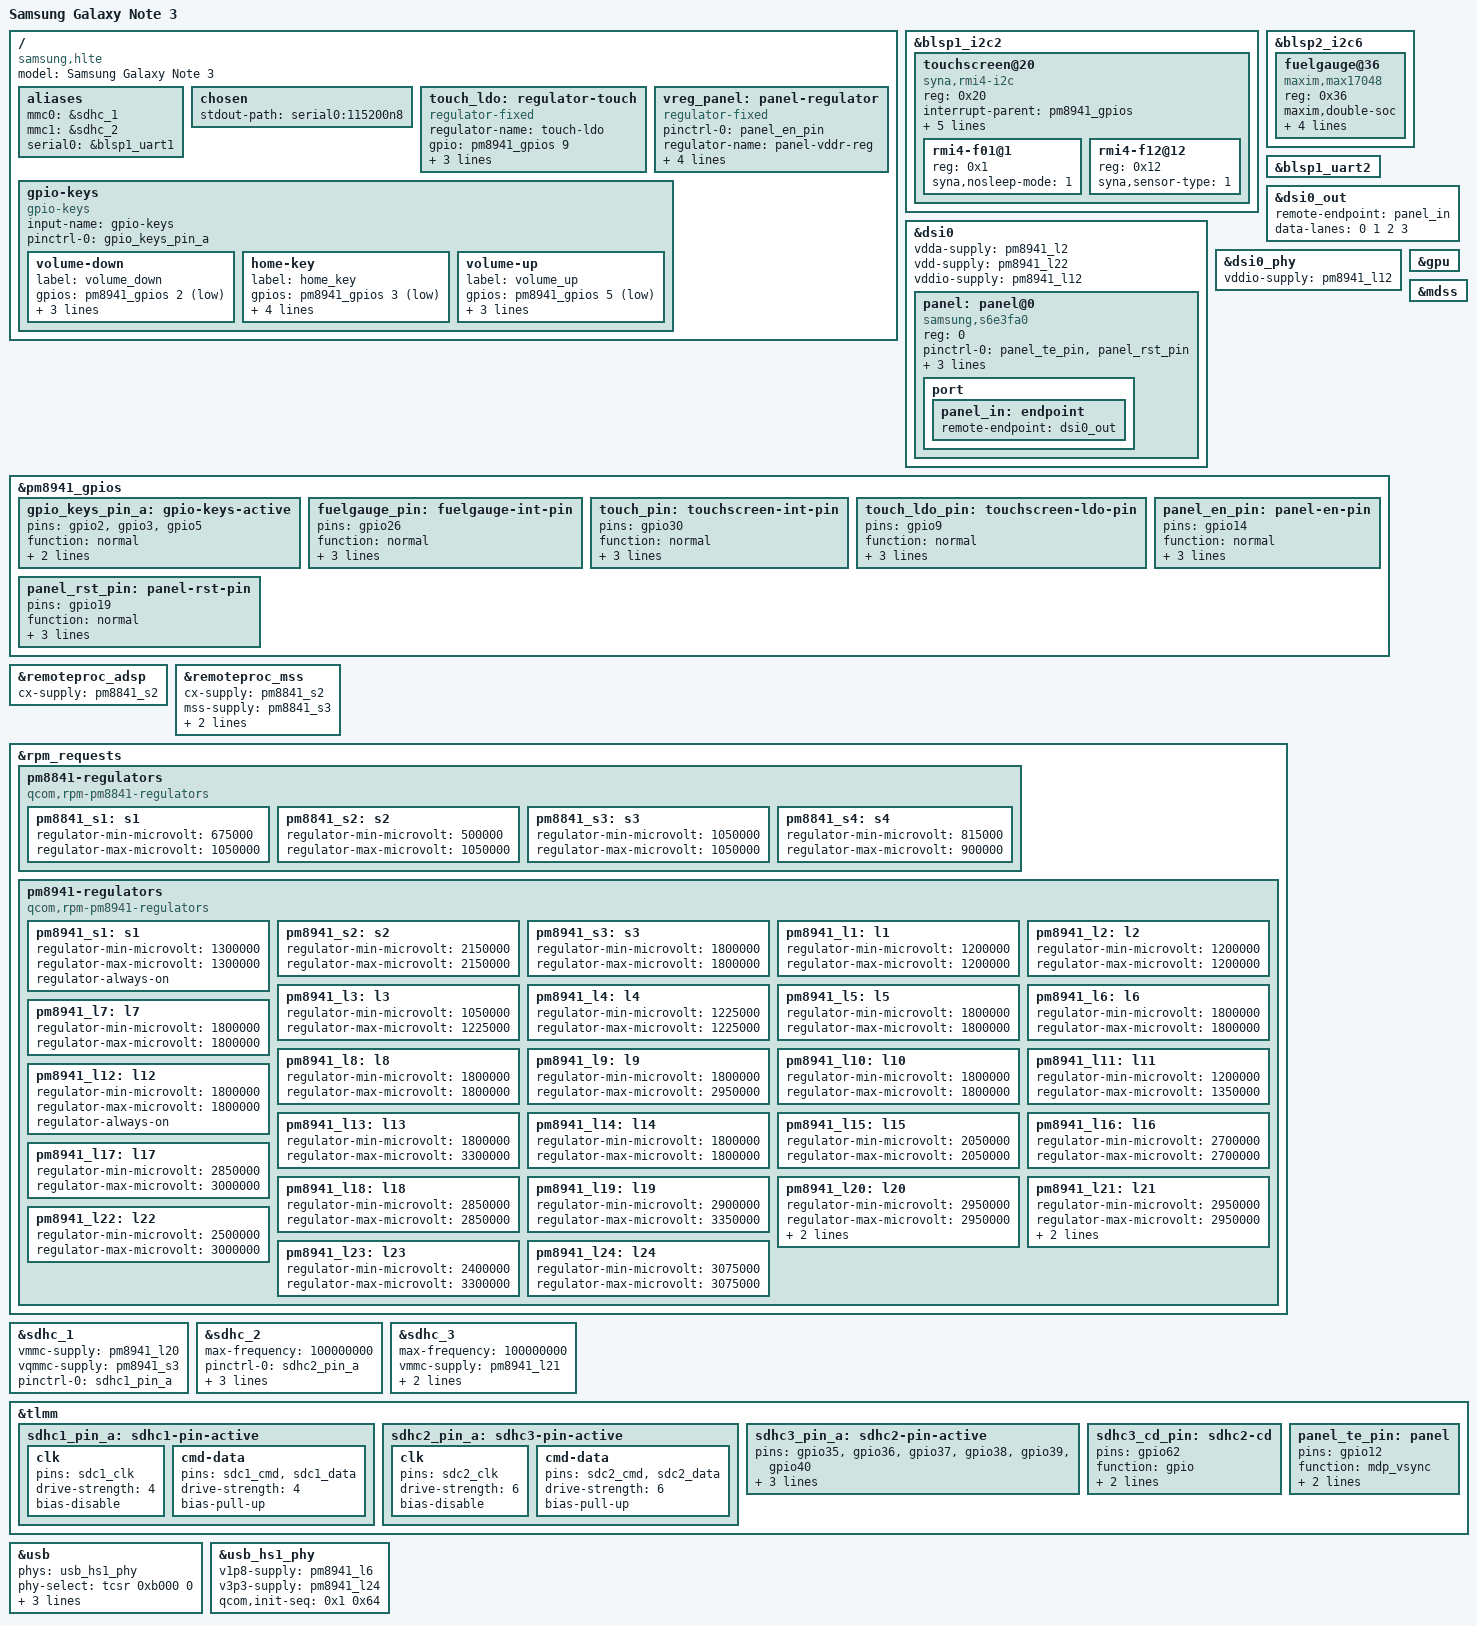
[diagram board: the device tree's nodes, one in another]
// SPDX-License-Identifier: GPL-2.0
#include "qcom-msm8974.dtsi"
#include "qcom-pm8841.dtsi"
#include "qcom-pm8941.dtsi"
#include <dt-bindings/input/input.h>
#include <dt-bindings/leds/common.h>
#include <dt-bindings/pinctrl/qcom,pmic-gpio.h>

/ {
	model = "Samsung Galaxy Note 3";
	compatible = "samsung,hlte", "qcom,msm8974";

	aliases {
		mmc0 = &sdhc_1; /* SDC1 eMMC slot */
		mmc1 = &sdhc_2; /* SDC2 SD card slot */
		serial0 = &blsp1_uart1;
	};

	chosen {
		stdout-path = "serial0:115200n8";
	};

	touch_ldo: regulator-touch {
		compatible = "regulator-fixed";
		regulator-name = "touch-ldo";
		gpio = <&pm8941_gpios 9 GPIO_ACTIVE_HIGH>;
		enable-active-high;
		regulator-boot-on;

		pinctrl-names = "default";
		pinctrl-0 = <&touch_ldo_pin>;
	};

	vreg_panel: panel-regulator {
		compatible = "regulator-fixed";

		pinctrl-names = "default";
		pinctrl-0 = <&panel_en_pin>;

		regulator-name = "panel-vddr-reg";
		regulator-min-microvolt = <1500000>;
		regulator-max-microvolt = <1500000>;

		gpio = <&pm8941_gpios 14 GPIO_ACTIVE_HIGH>;
		enable-active-high;
	};

	gpio-keys {
		compatible = "gpio-keys";
		input-name = "gpio-keys";

		pinctrl-names = "default";
		pinctrl-0 = <&gpio_keys_pin_a>;

		volume-down {
			label = "volume_down";
			gpios = <&pm8941_gpios 2 GPIO_ACTIVE_LOW>;
			linux,input-type = <1>;
			linux,code = <KEY_VOLUMEDOWN>;
			debounce-interval = <15>;
		};

		home-key {
			label = "home_key";
			gpios = <&pm8941_gpios 3 GPIO_ACTIVE_LOW>;
			linux,input-type = <1>;
			linux,code = <KEY_HOMEPAGE>;
			wakeup-source;
			debounce-interval = <15>;
		};

		volume-up {
			label = "volume_up";
			gpios = <&pm8941_gpios 5 GPIO_ACTIVE_LOW>;
			linux,input-type = <1>;
			linux,code = <KEY_VOLUMEUP>;
			debounce-interval = <15>;
		};
	};
};

&blsp1_i2c2 {
	status = "okay";

	touchscreen@20 {
		compatible = "syna,rmi4-i2c";
		reg = <0x20>;

		interrupt-parent = <&pm8941_gpios>;
		interrupts = <30 IRQ_TYPE_EDGE_FALLING>;

		vdd-supply = <&pm8941_l10>;
		vio-supply = <&touch_ldo>;

		pinctrl-names = "default";
		pinctrl-0 = <&touch_pin>;

		syna,startup-delay-ms = <100>;

		#address-cells = <1>;
		#size-cells = <0>;

		rmi4-f01@1 {
			reg = <0x1>;
			syna,nosleep-mode = <1>;
		};

		rmi4-f12@12 {
			reg = <0x12>;
			syna,sensor-type = <1>;
		};
	};
};

&blsp2_i2c6 {
	status = "okay";

	fuelgauge@36 {
		compatible = "maxim,max17048";
		reg = <0x36>;

		maxim,double-soc;
		maxim,rcomp = /bits/ 8 <0x56>;

		interrupt-parent = <&pm8941_gpios>;
		interrupts = <26 IRQ_TYPE_EDGE_FALLING>;

		pinctrl-names = "default";
		pinctrl-0 = <&fuelgauge_pin>;
	};
};

&blsp1_uart2 {
	status = "okay";
};

&dsi0 {
	status = "okay";

	vdda-supply = <&pm8941_l2>;
	vdd-supply = <&pm8941_l22>;
	vddio-supply = <&pm8941_l12>;

	panel: panel@0 {
		reg = <0>;
		compatible = "samsung,s6e3fa0";

		pinctrl-names = "default";
		pinctrl-0 = <&panel_te_pin &panel_rst_pin>;

		iovdd-supply = <&pm8941_l12>;
		vddr-supply = <&vreg_panel>;

		reset-gpios = <&pm8941_gpios 19 GPIO_ACTIVE_LOW>;

		port {
			panel_in: endpoint {
				remote-endpoint = <&dsi0_out>;
			};
		};
	};
};

&dsi0_out {
	remote-endpoint = <&panel_in>;
	data-lanes = <0 1 2 3>;
};

&dsi0_phy {
	status = "okay";

	vddio-supply = <&pm8941_l12>;
};

&gpu {
	status = "okay";
};

&mdss {
	status = "okay";
};

&pm8941_gpios {
	gpio_keys_pin_a: gpio-keys-active {
		pins = "gpio2", "gpio3", "gpio5";
		function = "normal";

		bias-pull-up;
		power-source = <PM8941_GPIO_S3>;
	};

	fuelgauge_pin: fuelgauge-int-pin {
		pins = "gpio26";
		function = "normal";
		bias-disable;
		input-enable;
		power-source = <PM8941_GPIO_S3>;
	};

	touch_pin: touchscreen-int-pin {
		pins = "gpio30";
		function = "normal";
		bias-disable;
		input-enable;
		power-source = <PM8941_GPIO_S3>;
	};

	touch_ldo_pin: touchscreen-ldo-pin {
		pins = "gpio9";
		function = "normal";

		output-high;
		power-source = <PM8941_GPIO_S3>;
		qcom,drive-strength = <PMIC_GPIO_STRENGTH_HIGH>;
	};

	panel_en_pin: panel-en-pin {
		pins = "gpio14";
		function = "normal";
		bias-pull-up;
		power-source = <PM8941_GPIO_S3>;
		qcom,drive-strength = <PMIC_GPIO_STRENGTH_LOW>;
	};

	panel_rst_pin: panel-rst-pin {
		pins = "gpio19";
		function = "normal";
		bias-disable;
		power-source = <PM8941_GPIO_S3>;
		qcom,drive-strength = <PMIC_GPIO_STRENGTH_LOW>;
	};
};

&remoteproc_adsp {
	cx-supply = <&pm8841_s2>;
};

&remoteproc_mss {
	cx-supply = <&pm8841_s2>;
	mss-supply = <&pm8841_s3>;
	mx-supply = <&pm8841_s1>;
	pll-supply = <&pm8941_l12>;
};

&rpm_requests {
	pm8841-regulators {
		compatible = "qcom,rpm-pm8841-regulators";

		pm8841_s1: s1 {
			regulator-min-microvolt = <675000>;
			regulator-max-microvolt = <1050000>;
		};

		pm8841_s2: s2 {
			regulator-min-microvolt = <500000>;
			regulator-max-microvolt = <1050000>;
		};

		pm8841_s3: s3 {
			regulator-min-microvolt = <1050000>;
			regulator-max-microvolt = <1050000>;
		};

		pm8841_s4: s4 {
			regulator-min-microvolt = <815000>;
			regulator-max-microvolt = <900000>;
		};
	};

	pm8941-regulators {
		compatible = "qcom,rpm-pm8941-regulators";

		pm8941_s1: s1 {
			regulator-min-microvolt = <1300000>;
			regulator-max-microvolt = <1300000>;
			regulator-always-on;
		};

		pm8941_s2: s2 {
			regulator-min-microvolt = <2150000>;
			regulator-max-microvolt = <2150000>;
		};

		pm8941_s3: s3 {
			regulator-min-microvolt = <1800000>;
			regulator-max-microvolt = <1800000>;
		};

		pm8941_l1: l1 {
			regulator-min-microvolt = <1200000>;
			regulator-max-microvolt = <1200000>;
		};

		pm8941_l2: l2 {
			regulator-min-microvolt = <1200000>;
			regulator-max-microvolt = <1200000>;
		};

		pm8941_l3: l3 {
			regulator-min-microvolt = <1050000>;
			regulator-max-microvolt = <1225000>;
		};

		pm8941_l4: l4 {
			regulator-min-microvolt = <1225000>;
			regulator-max-microvolt = <1225000>;
		};

		pm8941_l5: l5 {
			regulator-min-microvolt = <1800000>;
			regulator-max-microvolt = <1800000>;
		};

		pm8941_l6: l6 {
			regulator-min-microvolt = <1800000>;
			regulator-max-microvolt = <1800000>;
		};

		pm8941_l7: l7 {
			regulator-min-microvolt = <1800000>;
			regulator-max-microvolt = <1800000>;
		};

		pm8941_l8: l8 {
			regulator-min-microvolt = <1800000>;
			regulator-max-microvolt = <1800000>;
		};

		pm8941_l9: l9 {
			regulator-min-microvolt = <1800000>;
			regulator-max-microvolt = <2950000>;
		};

		pm8941_l10: l10 {
			regulator-min-microvolt = <1800000>;
			regulator-max-microvolt = <1800000>;
		};

		pm8941_l11: l11 {
			regulator-min-microvolt = <1200000>;
			regulator-max-microvolt = <1350000>;
		};

		pm8941_l12: l12 {
			regulator-min-microvolt = <1800000>;
			regulator-max-microvolt = <1800000>;
			regulator-always-on;
		};

		pm8941_l13: l13 {
			regulator-min-microvolt = <1800000>;
			regulator-max-microvolt = <3300000>;
		};

		pm8941_l14: l14 {
			regulator-min-microvolt = <1800000>;
			regulator-max-microvolt = <1800000>;
		};

		pm8941_l15: l15 {
			regulator-min-microvolt = <2050000>;
			regulator-max-microvolt = <2050000>;
		};

		pm8941_l16: l16 {
			regulator-min-microvolt = <2700000>;
			regulator-max-microvolt = <2700000>;
		};

		pm8941_l17: l17 {
			regulator-min-microvolt = <2850000>;
			regulator-max-microvolt = <3000000>;
		};

		pm8941_l18: l18 {
			regulator-min-microvolt = <2850000>;
			regulator-max-microvolt = <2850000>;
		};

		pm8941_l19: l19 {
			regulator-min-microvolt = <2900000>;
			regulator-max-microvolt = <3350000>;
		};

		pm8941_l20: l20 {
			regulator-min-microvolt = <2950000>;
			regulator-max-microvolt = <2950000>;

			regulator-allow-set-load;
			regulator-system-load = <200000>;
		};

		pm8941_l21: l21 {
			regulator-min-microvolt = <2950000>;
			regulator-max-microvolt = <2950000>;

			regulator-allow-set-load;
			regulator-system-load = <200000>;
		};

		pm8941_l22: l22 {
			regulator-min-microvolt = <2500000>;
			regulator-max-microvolt = <3000000>;
		};

		pm8941_l23: l23 {
			regulator-min-microvolt = <2400000>;
			regulator-max-microvolt = <3300000>;
		};

		pm8941_l24: l24 {
			regulator-min-microvolt = <3075000>;
			regulator-max-microvolt = <3075000>;
		};
	};
};

&sdhc_1 {
	status = "okay";

	vmmc-supply = <&pm8941_l20>;
	vqmmc-supply = <&pm8941_s3>;

	pinctrl-names = "default";
	pinctrl-0 = <&sdhc1_pin_a>;
};

&sdhc_2 {
	status = "okay";

	max-frequency = <100000000>;

	pinctrl-names = "default";
	pinctrl-0 = <&sdhc2_pin_a>;

	vmmc-supply = <&pm8941_l21>;
	vqmmc-supply = <&pm8941_l21>;

	non-removable;
};

&sdhc_3 {
	status = "okay";

	max-frequency = <100000000>;

	vmmc-supply = <&pm8941_l21>;
	vqmmc-supply = <&pm8941_l21>;

	/* cd-gpio is intentionally disabled. If enabled, an SD card
	 * present during boot is not initialized correctly. Without
	 * cd-gpios the driver resorts to polling, so hotplug works.
	 */
	pinctrl-names = "default";
	pinctrl-0 = <&sdhc3_pin_a /* &sdhc3_cd_pin */>;
	// cd-gpios = <&msmgpio 62 GPIO_ACTIVE_LOW>;
};

&tlmm {
	sdhc1_pin_a: sdhc1-pin-active {
		clk {
			pins = "sdc1_clk";
			drive-strength = <4>;
			bias-disable;
		};

		cmd-data {
			pins = "sdc1_cmd", "sdc1_data";
			drive-strength = <4>;
			bias-pull-up;
		};
	};

	sdhc2_pin_a: sdhc3-pin-active {
		clk {
			pins = "sdc2_clk";
			drive-strength = <6>;
			bias-disable;
		};

		cmd-data {
			pins = "sdc2_cmd", "sdc2_data";
			drive-strength = <6>;
			bias-pull-up;
		};
	};

	sdhc3_pin_a: sdhc2-pin-active {
		pins = "gpio35", "gpio36", "gpio37", "gpio38",
			"gpio39", "gpio40";
		function = "sdc3";
		drive-strength = <8>;
		bias-disable;
	};

	sdhc3_cd_pin: sdhc2-cd {
		pins = "gpio62";
		function = "gpio";
		drive-strength = <2>;
		bias-disable;
	};

	panel_te_pin: panel {
		pins = "gpio12";
		function = "mdp_vsync";
		drive-strength = <2>;
		bias-disable;
	};
};

&usb {
	phys = <&usb_hs1_phy>;
	phy-select = <&tcsr 0xb000 0>;
	/*extcon = <&smbb>, <&usb_id>;*/
	/*vbus-supply = <&chg_otg>;*/

	hnp-disable;
	srp-disable;
	adp-disable;

	status = "okay";
};

&usb_hs1_phy {
	v1p8-supply = <&pm8941_l6>;
	v3p3-supply = <&pm8941_l24>;

	/*extcon = <&smbb>;*/
	qcom,init-seq = /bits/ 8 <0x1 0x64>;

	status = "okay";
};
